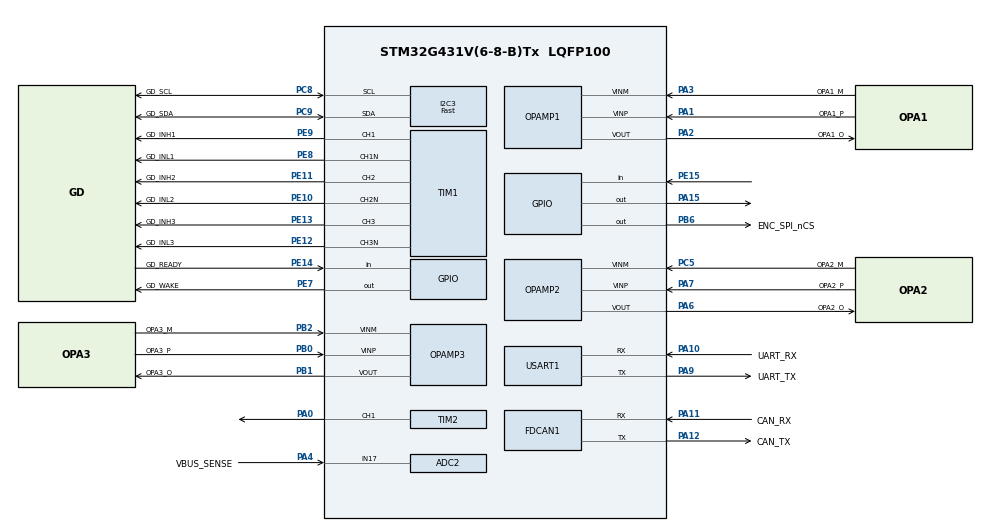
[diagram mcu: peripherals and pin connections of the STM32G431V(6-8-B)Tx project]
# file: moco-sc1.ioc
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ADC1.ClockPrescaler=ADC_CLOCK_ASYNC_DIV4
ADC1.EnableInjectedConversion=ENABLE
ADC1.EnableRegularConversion=DISABLE
ADC1.ExternalTrigInjecConv=ADC_EXTERNALTRIGINJEC_T1_TRGO
ADC1.InjNumberOfConversion=1
ADC1.InjectedChannel-1\#ChannelInjectedConversion=ADC_CHANNEL_3
ADC1.InjectedOffsetNumber-1\#ChannelInjectedConversion=ADC_OFFSET_NONE
ADC1.InjectedRank-1\#ChannelInjectedConversion=1
ADC1.InjectedSamplingTime-1\#ChannelInjectedConversion=ADC_SAMPLETIME_6CYCLES_5
ADC1.Rank1_Channel=ADC_CHANNEL_3
ADC1.master=1
ADC2.ClockPrescaler=ADC_CLOCK_ASYNC_DIV4
ADC2.EnableInjectedConversion=ENABLE
ADC2.EnableRegularConversion=DISABLE
ADC2.ExternalTrigInjecConv=ADC_EXTERNALTRIGINJEC_T1_TRGO
ADC2.InjNumberOfConversion=1
ADC2.InjectedChannel-1\#ChannelInjectedConversion=ADC_CHANNEL_3
ADC2.InjectedOffsetNumber-1\#ChannelInjectedConversion=ADC_OFFSET_NONE
ADC2.InjectedRank-1\#ChannelInjectedConversion=1
ADC2.InjectedSamplingTime-1\#ChannelInjectedConversion=ADC_SAMPLETIME_6CYCLES_5
ADC2.Overrun=ADC_OVR_DATA_OVERWRITTEN
ADC2.Rank1_Channel=ADC_CHANNEL_3
FDCAN1.CalculateBaudRateNominal=1750000
FDCAN1.CalculateTimeBitNominal=571
FDCAN1.CalculateTimeQuantumNominal=114.28571428571429
I2C3.CustomTiming=Disabled
I2C3.I2C_Speed_Mode=I2C_Fast
I2C3.Timing=0x00D04BFF
Mcu.Family=STM32G4
Mcu.Name=STM32G431V(6-8-B)Tx
Mcu.Package=LQFP100
NVIC.ADC1_2_IRQn=true\:1\:0\:true\:false\:true\:true\:true\:true
NVIC.I2C3_EV_IRQn=true\:1\:1\:true\:false\:true\:true\:true\:true
NVIC.PriorityGroup=NVIC_PRIORITYGROUP_3
NVIC.TIM2_IRQn=true\:5\:1\:true\:false\:true\:true\:true\:true
NVIC.TIM3_IRQn=true\:1\:0\:true\:false\:true\:true\:true\:true
NVIC.USART1_IRQn=true\:2\:0\:true\:false\:true\:true\:true\:true
PA0.Signal=S_TIM2_CH1
PA1.GPIO_Label=OPA1_P
PA1.Mode=Standalone
PA1.Signal=OPAMP1_VINP
PA10.GPIO_Label=UART_RX
PA10.GPIO_Speed=GPIO_SPEED_FREQ_HIGH
PA10.Mode=Asynchronous
PA10.Signal=USART1_RX
PA11.GPIO_Label=CAN_RX
PA11.GPIO_Speed=GPIO_SPEED_FREQ_HIGH
PA11.Mode=FDCAN_Activate
PA11.Signal=FDCAN1_RX
PA12.GPIO_Label=CAN_TX
PA12.GPIO_Speed=GPIO_SPEED_FREQ_HIGH
PA12.Mode=FDCAN_Activate
PA12.Signal=FDCAN1_TX
PA13.GPIO_Label=SWDIO
PA13.Mode=Serial_Wire
PA13.Signal=SYS_JTMS-SWDIO
PA14.GPIO_Label=SWCLK
PA14.Mode=Serial_Wire
PA14.Signal=SYS_JTCK-SWCLK
PA15.Signal=GPIO_Output
PA2.GPIO_Label=OPA1_O
PA2.Signal=SharedAnalog_PA2
PA3.GPIO_Label=OPA1_M
PA3.Mode=Standalone
PA3.Signal=OPAMP1_VINM
PA4.GPIO_Label=VBUS_SENSE
PA4.Mode=IN17-Single-Ended
PA4.Signal=ADC2_IN17
PA6.GPIO_Label=OPA2_O
PA6.Signal=SharedAnalog_PA6
PA7.GPIO_Label=OPA2_P
PA7.Mode=Standalone
PA7.Signal=OPAMP2_VINP
PA9.GPIO_Label=UART_TX
PA9.GPIO_Speed=GPIO_SPEED_FREQ_HIGH
PA9.Mode=Asynchronous
PA9.Signal=USART1_TX
PB0.GPIO_Label=OPA3_P
PB0.Mode=Standalone
PB0.Signal=OPAMP3_VINP
PB1.GPIO_Label=OPA3_O
PB1.Signal=SharedAnalog_PB1
PB2.GPIO_Label=OPA3_M
PB2.Mode=Standalone
PB2.Signal=OPAMP3_VINM
PB3.Signal=SPI3_SCK
PB4.GPIO_Label=ENC_SPI_MISO
PB4.GPIO_Speed=GPIO_SPEED_FREQ_HIGH
PB4.Signal=SPI1_MISO
PB5.GPIO_Label=ENC_SPI_MOSI
PB5.GPIO_Speed=GPIO_SPEED_FREQ_HIGH
PB5.Signal=SPI1_MOSI
PB6.GPIO_Label=ENC_SPI_nCS
PB6.GPIO_Speed=GPIO_SPEED_FREQ_LOW
PB6.Signal=GPIO_Output
PC5.GPIO_Label=OPA2_M
PC5.Mode=Standalone
PC5.Signal=OPAMP2_VINM
PC8.GPIO_Label=GD_SCL
PC8.GPIO_Speed=GPIO_SPEED_FREQ_HIGH
PC8.Mode=I2C
PC8.Signal=I2C3_SCL
PC9.GPIO_Label=GD_SDA
PC9.GPIO_Speed=GPIO_SPEED_FREQ_HIGH
PC9.Mode=I2C
PC9.Signal=I2C3_SDA
PE10.GPIO_Label=GD_INL2
PE10.GPIO_Speed=GPIO_SPEED_FREQ_VERY_HIGH
PE10.Mode=PWM Generation2 CH2 CH2N
PE10.Signal=TIM1_CH2N
PE11.GPIO_Label=GD_INH2
PE11.GPIO_Speed=GPIO_SPEED_FREQ_VERY_HIGH
PE11.Signal=S_TIM1_CH2
PE12.GPIO_Label=GD_INL3
PE12.GPIO_Speed=GPIO_SPEED_FREQ_VERY_HIGH
PE12.Mode=PWM Generation3 CH3 CH3N
PE12.Signal=TIM1_CH3N
PE13.GPIO_Label=GD_INH3
PE13.GPIO_Speed=GPIO_SPEED_FREQ_VERY_HIGH
PE13.Signal=S_TIM1_CH3
PE14.GPIO_Label=GD_READY
PE14.GPIO_PuPd=GPIO_PULLUP
PE14.Signal=GPIO_Input
PE15.Signal=GPIO_Input
PE7.GPIO_Label=GD_WAKE
PE7.GPIO_Speed=GPIO_SPEED_FREQ_LOW
PE7.Signal=GPIO_Output
PE8.GPIO_Label=GD_INL1
PE8.GPIO_Speed=GPIO_SPEED_FREQ_VERY_HIGH
PE8.Mode=PWM Generation1 CH1 CH1N
PE8.Signal=TIM1_CH1N
PE9.GPIO_Label=GD_INH1
PE9.GPIO_Speed=GPIO_SPEED_FREQ_VERY_HIGH
PE9.Signal=S_TIM1_CH1
PF0-OSC_IN.Mode=HSE-External-Oscillator
PF0-OSC_IN.Signal=RCC_OSC_IN
PF1-OSC_OUT.Mode=HSE-External-Oscillator
PF1-OSC_OUT.Signal=RCC_OSC_OUT
ProjectManager.HeapSize=0x200
ProjectManager.StackSize=0x400
ProjectManager.TargetToolchain=STM32CubeIDE
RCC.ADC12Freq_Value=140000000
RCC.AHBFreq_Value=140000000
RCC.APB1Freq_Value=140000000
RCC.APB1TimFreq_Value=140000000
RCC.APB2Freq_Value=140000000
RCC.APB2TimFreq_Value=140000000
RCC.CortexFreq_Value=140000000
RCC.EXTERNAL_CLOCK_VALUE=12288000
RCC.HCLKFreq_Value=140000000
RCC.HSE_VALUE=16000000
RCC.HSI48_VALUE=48000000
RCC.HSI_VALUE=16000000
RCC.LSE_VALUE=32768
RCC.PLLM=RCC_PLLM_DIV2
RCC.PLLN=35
RCC.PLLQ=RCC_PLLQ_DIV4
RCC.SYSCLKFreq_VALUE=140000000
RCC.SYSCLKSource=RCC_SYSCLKSOURCE_PLLCLK
RCC.USBFreq_Value=70000000
RCC.VCOOutputFreq_Value=280000000
SH.S_TIM1_CH1.0=TIM1_CH1,PWM Generation1 CH1 CH1N
SH.S_TIM1_CH2.0=TIM1_CH2,PWM Generation2 CH2 CH2N
SH.S_TIM1_CH3.0=TIM1_CH3,PWM Generation3 CH3 CH3N
SH.S_TIM2_CH1.0=TIM2_CH1,PWM Generation1 CH1
SH.SharedAnalog_PA2.0=OPAMP1_VOUT,Standalone
SH.SharedAnalog_PA2.1=ADC1_IN3,IN3-Single-Ended
SH.SharedAnalog_PA6.0=OPAMP2_VOUT,Standalone
SH.SharedAnalog_PA6.1=ADC2_IN3,IN3-Single-Ended
SH.SharedAnalog_PB1.0=OPAMP3_VOUT,Standalone
SH.SharedAnalog_PB1.1=ADC1_IN12,IN12-Single-Ended
STMicroelectronics.X-CUBE-AZRTOS-G4.2.0.0.TX_APP_CREATION=1
STMicroelectronics.X-CUBE-AZRTOS-G4.2.0.0.TX_APP_GENERATE_INIT_CODE=true
STMicroelectronics.X-CUBE-AZRTOS-G4.2.0.0_IsAnAzureRtosMw=true
TIM1.AutoReloadPreload=TIM_AUTORELOAD_PRELOAD_DISABLE
TIM1.Break2Polarity=TIM_BREAK2POLARITY_LOW
TIM1.BreakPolarity=TIM_BREAKPOLARITY_LOW
TIM1.Channel-PWM\ Generation1\ CH1\ CH1N=TIM_CHANNEL_1
TIM1.Channel-PWM\ Generation2\ CH2\ CH2N=TIM_CHANNEL_2
TIM1.Channel-PWM\ Generation3\ CH3\ CH3N=TIM_CHANNEL_3
TIM1.Channel-PWM\ Generation4\ No\ Output=TIM_CHANNEL_4
TIM1.ClockDivision=TIM_CLOCKDIVISION_DIV1
TIM1.CounterMode=TIM_COUNTERMODE_CENTERALIGNED1
TIM1.DeadTime=GD_PWM_TIM_DTG
TIM1.OCMode_PWM-PWM\ Generation4\ No\ Output=TIM_OCMODE_PWM2
TIM1.OCNPolarity_1=TIM_OCNPOLARITY_HIGH
TIM1.OCNPolarity_2=TIM_OCNPOLARITY_HIGH
TIM1.OCNPolarity_3=TIM_OCNPOLARITY_HIGH
TIM1.PeriodNoDither=GD_PWM_TIM_ARR
TIM1.Prescaler=GD_PWM_TIM_PSC
TIM1.PulseNoDither_1=0
TIM1.PulseNoDither_2=0
TIM1.PulseNoDither_3=0
TIM1.RepetitionCounter=0
TIM1.TIM_MasterOutputTrigger=TIM_TRGO_OC4REF
TIM2.AutoReloadPreload=TIM_AUTORELOAD_PRELOAD_DISABLE
TIM2.Channel-PWM\ Generation1\ CH1=TIM_CHANNEL_1
TIM2.PeriodNoDither=HB_LED_TIM_ARR
TIM2.Prescaler=HB_LED_TIM_PSC
TIM3.PeriodNoDither=ML_TIM_ARR
TIM3.Prescaler=ML_TIM_PSC
TIM8.PeriodNoDither=249
TIM8.Prescaler=27
USART1.FIFOMode=FIFOMODE_ENABLE
USART1.VirtualMode-Asynchronous=VM_ASYNC
VP_SYS_VS_DBSignals.Mode=DisableDeadBatterySignals
VP_SYS_V_VREFBUF.Mode=ExternalMode
VP_TIM16_VS_ClockSourceINT.Mode=Enable_Timer
VP_TIM1_VS_ClockSourceINT.Mode=Internal
VP_TIM1_VS_no_output4.Mode=PWM Generation4 No Output
VP_TIM2_VS_ClockSourceINT.Mode=Internal
VP_TIM3_VS_ClockSourceINT.Mode=Internal
VP_TIM8_VS_ClockSourceINT.Mode=Internal
board=custom

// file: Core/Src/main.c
/* USER CODE BEGIN Header */
/**
  ******************************************************************************
  * @file           : main.c
  * @brief          : Main program body
  ******************************************************************************
  * @attention
  *
  * Copyright (c) 2024 STMicroelectronics.
  * All rights reserved.
  *
  * This software is licensed under terms that can be found in the LICENSE file
  * in the root directory of this software component.
  * If no LICENSE file comes with this software, it is provided AS-IS.
  *
  ******************************************************************************
  */
/* USER CODE END Header */
#include "main.h"

/* USER CODE BEGIN Includes */
#include "stspin32g4_gate_driver.h"
#include "heartbeat.h"
#include "stspin32g4.h"
/* USER CODE END Includes */

FDCAN_HandleTypeDef hfdcan1;

OPAMP_HandleTypeDef hopamp1;
OPAMP_HandleTypeDef hopamp2;
OPAMP_HandleTypeDef hopamp3;

void SystemClock_Config(void);
static void MX_GPIO_Init(void);
static void MX_ADC2_Init(void);
static void MX_FDCAN1_Init(void);
static void MX_I2C3_Init(void);
static void MX_OPAMP1_Init(void);
static void MX_OPAMP2_Init(void);
static void MX_OPAMP3_Init(void);
static void MX_TIM1_Init(void);
static void MX_TIM16_Init(void);
static void MX_USART1_UART_Init(void);
static void MX_TIM2_Init(void);
static void MX_TIM8_Init(void);
static void MX_TIM3_Init(void);
static void MX_ADC1_Init(void);

/* USER CODE BEGIN 0 */
extern float act;
/* USER CODE END 0 */

int main(void)
{

  /* MCU Configuration--------------------------------------------------------*/

  /* Reset of all peripherals, Initializes the Flash interface and the Systick. */
  HAL_Init();

  /* Configure the system clock */
  SystemClock_Config();

  /* Initialize all configured peripherals */
  MX_GPIO_Init();
  MX_ADC2_Init();
  MX_FDCAN1_Init();
  MX_I2C3_Init();
  MX_OPAMP1_Init();
  MX_OPAMP2_Init();
  MX_OPAMP3_Init();
  MX_TIM1_Init();
  MX_TIM16_Init();
  MX_USART1_UART_Init();
  MX_TIM2_Init();
  MX_TIM8_Init();
  MX_TIM3_Init();
  MX_ADC1_Init();
  /* USER CODE BEGIN 2 */
  heartbeat_init();
  spg4_init();
  gd_init();
  /* USER CODE END 2 */

  /* Infinite loop */
  /* USER CODE BEGIN WHILE */
  LL_USART_TransmitData8(USART1, 0x41);
  while (1)
  {
    /* USER CODE END WHILE */

    /* USER CODE BEGIN 3 */
    LL_USART_TransmitData8(USART1, act);
    LL_USART_TransmitData8(USART1, 0xFE);
    gd_clear_fault();

    //LL_USART_TransmitData8(USART1, (uint8_t)vbus_adc);

    //spg4_set_pwm(60, 0, 0);
    HAL_Delay(500);
  }
  /* USER CODE END 3 */
}

void SystemClock_Config(void)
{
  LL_FLASH_SetLatency(LL_FLASH_LATENCY_4);
  while(LL_FLASH_GetLatency() != LL_FLASH_LATENCY_4)
  {
  }
  LL_PWR_SetRegulVoltageScaling(LL_PWR_REGU_VOLTAGE_SCALE1);
  LL_RCC_HSI_Enable();
   /* Wait till HSI is ready */
  while(LL_RCC_HSI_IsReady() != 1)
  {
  }

  LL_RCC_HSI_SetCalibTrimming(64);
  LL_RCC_PLL_ConfigDomain_SYS(LL_RCC_PLLSOURCE_HSI, LL_RCC_PLLM_DIV_2, 35, LL_RCC_PLLR_DIV_2);
  LL_RCC_PLL_EnableDomain_SYS();
  LL_RCC_PLL_Enable();
   /* Wait till PLL is ready */
  while(LL_RCC_PLL_IsReady() != 1)
  {
  }

  LL_RCC_SetSysClkSource(LL_RCC_SYS_CLKSOURCE_PLL);
  LL_RCC_SetAHBPrescaler(LL_RCC_SYSCLK_DIV_2);
   /* Wait till System clock is ready */
  while(LL_RCC_GetSysClkSource() != LL_RCC_SYS_CLKSOURCE_STATUS_PLL)
  {
  }

  /* Insure 1us transition state at intermediate medium speed clock*/
  for (__IO uint32_t i = (170 >> 1); i !=0; i--);

  /* Set AHB prescaler*/
  LL_RCC_SetAHBPrescaler(LL_RCC_SYSCLK_DIV_1);
  LL_RCC_SetAPB1Prescaler(LL_RCC_APB1_DIV_1);
  LL_RCC_SetAPB2Prescaler(LL_RCC_APB2_DIV_1);
  LL_SetSystemCoreClock(140000000);

   /* Update the time base */
  if (HAL_InitTick (TICK_INT_PRIORITY) != HAL_OK)
  {
    Error_Handler();
  }
}

static void MX_ADC1_Init(void)
{

  LL_ADC_InitTypeDef ADC_InitStruct = {0};
  LL_ADC_REG_InitTypeDef ADC_REG_InitStruct = {0};
  LL_ADC_CommonInitTypeDef ADC_CommonInitStruct = {0};
  LL_ADC_INJ_InitTypeDef ADC_INJ_InitStruct = {0};

  LL_GPIO_InitTypeDef GPIO_InitStruct = {0};

  LL_RCC_SetADCClockSource(LL_RCC_ADC12_CLKSOURCE_SYSCLK);

  /* Peripheral clock enable */
  LL_AHB2_GRP1_EnableClock(LL_AHB2_GRP1_PERIPH_ADC12);

  LL_AHB2_GRP1_EnableClock(LL_AHB2_GRP1_PERIPH_GPIOA);
  LL_AHB2_GRP1_EnableClock(LL_AHB2_GRP1_PERIPH_GPIOB);
  /**ADC1 GPIO Configuration
  PA2   ------> ADC1_IN3
  PB1   ------> ADC1_IN12
  */
  GPIO_InitStruct.Pin = OPA1_O_Pin;
  GPIO_InitStruct.Mode = LL_GPIO_MODE_ANALOG;
  GPIO_InitStruct.Pull = LL_GPIO_PULL_NO;
  LL_GPIO_Init(OPA1_O_GPIO_Port, &GPIO_InitStruct);

  GPIO_InitStruct.Pin = OPA3_O_Pin;
  GPIO_InitStruct.Mode = LL_GPIO_MODE_ANALOG;
  GPIO_InitStruct.Pull = LL_GPIO_PULL_NO;
  LL_GPIO_Init(OPA3_O_GPIO_Port, &GPIO_InitStruct);

  /* ADC1 interrupt Init */
  NVIC_SetPriority(ADC1_2_IRQn, NVIC_EncodePriority(NVIC_GetPriorityGrouping(),1, 0));
  NVIC_EnableIRQ(ADC1_2_IRQn);

  /** Common config
  */
  ADC_InitStruct.Resolution = LL_ADC_RESOLUTION_12B;
  ADC_InitStruct.DataAlignment = LL_ADC_DATA_ALIGN_RIGHT;
  ADC_InitStruct.LowPowerMode = LL_ADC_LP_MODE_NONE;
  LL_ADC_Init(ADC1, &ADC_InitStruct);
  ADC_REG_InitStruct.SequencerLength = LL_ADC_REG_SEQ_SCAN_DISABLE;
  ADC_REG_InitStruct.SequencerDiscont = LL_ADC_REG_SEQ_DISCONT_DISABLE;
  ADC_REG_InitStruct.ContinuousMode = LL_ADC_REG_CONV_SINGLE;
  ADC_REG_InitStruct.DMATransfer = LL_ADC_REG_DMA_TRANSFER_NONE;
  ADC_REG_InitStruct.Overrun = LL_ADC_REG_OVR_DATA_PRESERVED;
  LL_ADC_REG_Init(ADC1, &ADC_REG_InitStruct);
  LL_ADC_SetGainCompensation(ADC1, 0);
  LL_ADC_SetOverSamplingScope(ADC1, LL_ADC_OVS_DISABLE);
  ADC_CommonInitStruct.CommonClock = LL_ADC_CLOCK_ASYNC_DIV4;
  ADC_CommonInitStruct.Multimode = LL_ADC_MULTI_INDEPENDENT;
  LL_ADC_CommonInit(__LL_ADC_COMMON_INSTANCE(ADC1), &ADC_CommonInitStruct);
  ADC_INJ_InitStruct.TriggerSource = LL_ADC_INJ_TRIG_EXT_TIM1_TRGO;
  ADC_INJ_InitStruct.SequencerLength = LL_ADC_INJ_SEQ_SCAN_DISABLE;
  ADC_INJ_InitStruct.SequencerDiscont = LL_ADC_INJ_SEQ_DISCONT_DISABLE;
  ADC_INJ_InitStruct.TrigAuto = LL_ADC_INJ_TRIG_INDEPENDENT;
  LL_ADC_INJ_Init(ADC1, &ADC_INJ_InitStruct);
  LL_ADC_INJ_SetQueueMode(ADC1, LL_ADC_INJ_QUEUE_DISABLE);
  LL_ADC_INJ_SetTriggerEdge(ADC1, LL_ADC_INJ_TRIG_EXT_RISING);

  /* Disable ADC deep power down (enabled by default after reset state) */
  LL_ADC_DisableDeepPowerDown(ADC1);
  /* Enable ADC internal voltage regulator */
  LL_ADC_EnableInternalRegulator(ADC1);
  /* Delay for ADC internal voltage regulator stabilization. */
  /* Compute number of CPU cycles to wait for, from delay in us. */
  /* Note: Variable divided by 2 to compensate partially */
  /* CPU processing cycles (depends on compilation optimization). */
  /* Note: If system core clock frequency is below 200kHz, wait time */
  /* is only a few CPU processing cycles. */
  uint32_t wait_loop_index;
  wait_loop_index = ((LL_ADC_DELAY_INTERNAL_REGUL_STAB_US * (SystemCoreClock / (100000 * 2))) / 10);
  while(wait_loop_index != 0)
  {
    wait_loop_index--;
  }

  /** Configure Injected Channel
  */
  LL_ADC_INJ_SetSequencerRanks(ADC1, LL_ADC_INJ_RANK_1, LL_ADC_CHANNEL_3);
  LL_ADC_SetChannelSamplingTime(ADC1, LL_ADC_CHANNEL_3, LL_ADC_SAMPLINGTIME_6CYCLES_5);
  LL_ADC_SetChannelSingleDiff(ADC1, LL_ADC_CHANNEL_3, LL_ADC_SINGLE_ENDED);

}

static void MX_ADC2_Init(void)
{

  LL_ADC_InitTypeDef ADC_InitStruct = {0};
  LL_ADC_REG_InitTypeDef ADC_REG_InitStruct = {0};
  LL_ADC_INJ_InitTypeDef ADC_INJ_InitStruct = {0};

  LL_GPIO_InitTypeDef GPIO_InitStruct = {0};

  LL_RCC_SetADCClockSource(LL_RCC_ADC12_CLKSOURCE_SYSCLK);

  /* Peripheral clock enable */
  LL_AHB2_GRP1_EnableClock(LL_AHB2_GRP1_PERIPH_ADC12);

  LL_AHB2_GRP1_EnableClock(LL_AHB2_GRP1_PERIPH_GPIOA);
  /**ADC2 GPIO Configuration
  PA4   ------> ADC2_IN17
  PA6   ------> ADC2_IN3
  */
  GPIO_InitStruct.Pin = VBUS_SENSE_Pin;
  GPIO_InitStruct.Mode = LL_GPIO_MODE_ANALOG;
  GPIO_InitStruct.Pull = LL_GPIO_PULL_NO;
  LL_GPIO_Init(VBUS_SENSE_GPIO_Port, &GPIO_InitStruct);

  GPIO_InitStruct.Pin = OPA2_O_Pin;
  GPIO_InitStruct.Mode = LL_GPIO_MODE_ANALOG;
  GPIO_InitStruct.Pull = LL_GPIO_PULL_NO;
  LL_GPIO_Init(OPA2_O_GPIO_Port, &GPIO_InitStruct);

  /* ADC2 interrupt Init */
  NVIC_SetPriority(ADC1_2_IRQn, NVIC_EncodePriority(NVIC_GetPriorityGrouping(),1, 0));
  NVIC_EnableIRQ(ADC1_2_IRQn);

  /** Common config
  */
  ADC_InitStruct.Resolution = LL_ADC_RESOLUTION_12B;
  ADC_InitStruct.DataAlignment = LL_ADC_DATA_ALIGN_RIGHT;
  ADC_InitStruct.LowPowerMode = LL_ADC_LP_MODE_NONE;
  LL_ADC_Init(ADC2, &ADC_InitStruct);
  ADC_REG_InitStruct.SequencerLength = LL_ADC_REG_SEQ_SCAN_DISABLE;
  ADC_REG_InitStruct.SequencerDiscont = LL_ADC_REG_SEQ_DISCONT_DISABLE;
  ADC_REG_InitStruct.ContinuousMode = LL_ADC_REG_CONV_SINGLE;
  ADC_REG_InitStruct.DMATransfer = LL_ADC_REG_DMA_TRANSFER_NONE;
  ADC_REG_InitStruct.Overrun = LL_ADC_REG_OVR_DATA_OVERWRITTEN;
  LL_ADC_REG_Init(ADC2, &ADC_REG_InitStruct);
  LL_ADC_SetGainCompensation(ADC2, 0);
  LL_ADC_SetOverSamplingScope(ADC2, LL_ADC_OVS_DISABLE);
  ADC_INJ_InitStruct.TriggerSource = LL_ADC_INJ_TRIG_EXT_TIM1_TRGO;
  ADC_INJ_InitStruct.SequencerLength = LL_ADC_INJ_SEQ_SCAN_DISABLE;
  ADC_INJ_InitStruct.SequencerDiscont = LL_ADC_INJ_SEQ_DISCONT_DISABLE;
  ADC_INJ_InitStruct.TrigAuto = LL_ADC_INJ_TRIG_INDEPENDENT;
  LL_ADC_INJ_Init(ADC2, &ADC_INJ_InitStruct);
  LL_ADC_INJ_SetQueueMode(ADC2, LL_ADC_INJ_QUEUE_DISABLE);
  LL_ADC_INJ_SetTriggerEdge(ADC2, LL_ADC_INJ_TRIG_EXT_RISING);

  /* Disable ADC deep power down (enabled by default after reset state) */
  LL_ADC_DisableDeepPowerDown(ADC2);
  /* Enable ADC internal voltage regulator */
  LL_ADC_EnableInternalRegulator(ADC2);
  /* Delay for ADC internal voltage regulator stabilization. */
  /* Compute number of CPU cycles to wait for, from delay in us. */
  /* Note: Variable divided by 2 to compensate partially */
  /* CPU processing cycles (depends on compilation optimization). */
  /* Note: If system core clock frequency is below 200kHz, wait time */
  /* is only a few CPU processing cycles. */
  uint32_t wait_loop_index;
  wait_loop_index = ((LL_ADC_DELAY_INTERNAL_REGUL_STAB_US * (SystemCoreClock / (100000 * 2))) / 10);
  while(wait_loop_index != 0)
  {
    wait_loop_index--;
  }

  /** Configure Injected Channel
  */
  LL_ADC_INJ_SetSequencerRanks(ADC2, LL_ADC_INJ_RANK_1, LL_ADC_CHANNEL_3);
  LL_ADC_SetChannelSamplingTime(ADC2, LL_ADC_CHANNEL_3, LL_ADC_SAMPLINGTIME_6CYCLES_5);
  LL_ADC_SetChannelSingleDiff(ADC2, LL_ADC_CHANNEL_3, LL_ADC_SINGLE_ENDED);

}

static void MX_FDCAN1_Init(void)
{

  hfdcan1.Instance = FDCAN1;
  hfdcan1.Init.ClockDivider = FDCAN_CLOCK_DIV1;
  hfdcan1.Init.FrameFormat = FDCAN_FRAME_CLASSIC;
  hfdcan1.Init.Mode = FDCAN_MODE_NORMAL;
  hfdcan1.Init.AutoRetransmission = DISABLE;
  hfdcan1.Init.TransmitPause = DISABLE;
  hfdcan1.Init.ProtocolException = DISABLE;
  hfdcan1.Init.NominalPrescaler = 16;
  hfdcan1.Init.NominalSyncJumpWidth = 1;
  hfdcan1.Init.NominalTimeSeg1 = 2;
  hfdcan1.Init.NominalTimeSeg2 = 2;
  hfdcan1.Init.DataPrescaler = 1;
  hfdcan1.Init.DataSyncJumpWidth = 1;
  hfdcan1.Init.DataTimeSeg1 = 1;
  hfdcan1.Init.DataTimeSeg2 = 1;
  hfdcan1.Init.StdFiltersNbr = 0;
  hfdcan1.Init.ExtFiltersNbr = 0;
  hfdcan1.Init.TxFifoQueueMode = FDCAN_TX_FIFO_OPERATION;
  if (HAL_FDCAN_Init(&hfdcan1) != HAL_OK)
  {
    Error_Handler();
  }

}

static void MX_I2C3_Init(void)
{

  LL_I2C_InitTypeDef I2C_InitStruct = {0};

  LL_GPIO_InitTypeDef GPIO_InitStruct = {0};

  LL_RCC_SetI2CClockSource(LL_RCC_I2C3_CLKSOURCE_PCLK1);

  LL_AHB2_GRP1_EnableClock(LL_AHB2_GRP1_PERIPH_GPIOC);
  /**I2C3 GPIO Configuration
  PC8   ------> I2C3_SCL
  PC9   ------> I2C3_SDA
  */
  GPIO_InitStruct.Pin = GD_SCL_Pin;
  GPIO_InitStruct.Mode = LL_GPIO_MODE_ALTERNATE;
  GPIO_InitStruct.Speed = LL_GPIO_SPEED_FREQ_HIGH;
  GPIO_InitStruct.OutputType = LL_GPIO_OUTPUT_OPENDRAIN;
  GPIO_InitStruct.Pull = LL_GPIO_PULL_NO;
  GPIO_InitStruct.Alternate = LL_GPIO_AF_8;
  LL_GPIO_Init(GD_SCL_GPIO_Port, &GPIO_InitStruct);

  GPIO_InitStruct.Pin = GD_SDA_Pin;
  GPIO_InitStruct.Mode = LL_GPIO_MODE_ALTERNATE;
  GPIO_InitStruct.Speed = LL_GPIO_SPEED_FREQ_HIGH;
  GPIO_InitStruct.OutputType = LL_GPIO_OUTPUT_OPENDRAIN;
  GPIO_InitStruct.Pull = LL_GPIO_PULL_NO;
  GPIO_InitStruct.Alternate = LL_GPIO_AF_8;
  LL_GPIO_Init(GD_SDA_GPIO_Port, &GPIO_InitStruct);

  /* Peripheral clock enable */
  LL_APB1_GRP1_EnableClock(LL_APB1_GRP1_PERIPH_I2C3);

  /* I2C3 interrupt Init */
  NVIC_SetPriority(I2C3_EV_IRQn, NVIC_EncodePriority(NVIC_GetPriorityGrouping(),1, 1));
  NVIC_EnableIRQ(I2C3_EV_IRQn);

  /** I2C Initialization
  */
  I2C_InitStruct.PeripheralMode = LL_I2C_MODE_I2C;
  I2C_InitStruct.Timing = 0x00D04BFF;
  I2C_InitStruct.AnalogFilter = LL_I2C_ANALOGFILTER_ENABLE;
  I2C_InitStruct.DigitalFilter = 0;
  I2C_InitStruct.OwnAddress1 = 0;
  I2C_InitStruct.TypeAcknowledge = LL_I2C_ACK;
  I2C_InitStruct.OwnAddrSize = LL_I2C_OWNADDRESS1_7BIT;
  LL_I2C_Init(I2C3, &I2C_InitStruct);
  LL_I2C_EnableAutoEndMode(I2C3);
  LL_I2C_SetOwnAddress2(I2C3, 0, LL_I2C_OWNADDRESS2_NOMASK);
  LL_I2C_DisableOwnAddress2(I2C3);
  LL_I2C_DisableGeneralCall(I2C3);
  LL_I2C_EnableClockStretching(I2C3);

}

static void MX_OPAMP1_Init(void)
{

  hopamp1.Instance = OPAMP1;
  hopamp1.Init.PowerMode = OPAMP_POWERMODE_NORMAL;
  hopamp1.Init.Mode = OPAMP_STANDALONE_MODE;
  hopamp1.Init.InvertingInput = OPAMP_INVERTINGINPUT_IO0;
  hopamp1.Init.NonInvertingInput = OPAMP_NONINVERTINGINPUT_IO0;
  hopamp1.Init.InternalOutput = DISABLE;
  hopamp1.Init.TimerControlledMuxmode = OPAMP_TIMERCONTROLLEDMUXMODE_DISABLE;
  hopamp1.Init.UserTrimming = OPAMP_TRIMMING_FACTORY;
  if (HAL_OPAMP_Init(&hopamp1) != HAL_OK)
  {
    Error_Handler();
  }

}

static void MX_OPAMP2_Init(void)
{

  hopamp2.Instance = OPAMP2;
  hopamp2.Init.PowerMode = OPAMP_POWERMODE_NORMAL;
  hopamp2.Init.Mode = OPAMP_STANDALONE_MODE;
  hopamp2.Init.InvertingInput = OPAMP_INVERTINGINPUT_IO1;
  hopamp2.Init.NonInvertingInput = OPAMP_NONINVERTINGINPUT_IO0;
  hopamp2.Init.InternalOutput = DISABLE;
  hopamp2.Init.TimerControlledMuxmode = OPAMP_TIMERCONTROLLEDMUXMODE_DISABLE;
  hopamp2.Init.UserTrimming = OPAMP_TRIMMING_FACTORY;
  if (HAL_OPAMP_Init(&hopamp2) != HAL_OK)
  {
    Error_Handler();
  }

}

static void MX_OPAMP3_Init(void)
{

  hopamp3.Instance = OPAMP3;
  hopamp3.Init.PowerMode = OPAMP_POWERMODE_NORMAL;
  hopamp3.Init.Mode = OPAMP_STANDALONE_MODE;
  hopamp3.Init.InvertingInput = OPAMP_INVERTINGINPUT_IO0;
  hopamp3.Init.NonInvertingInput = OPAMP_NONINVERTINGINPUT_IO0;
  hopamp3.Init.InternalOutput = DISABLE;
  hopamp3.Init.TimerControlledMuxmode = OPAMP_TIMERCONTROLLEDMUXMODE_DISABLE;
  hopamp3.Init.UserTrimming = OPAMP_TRIMMING_FACTORY;
  if (HAL_OPAMP_Init(&hopamp3) != HAL_OK)
  {
    Error_Handler();
  }

}

static void MX_TIM1_Init(void)
{

  LL_TIM_InitTypeDef TIM_InitStruct = {0};
  LL_TIM_OC_InitTypeDef TIM_OC_InitStruct = {0};
  LL_TIM_BDTR_InitTypeDef TIM_BDTRInitStruct = {0};

  LL_GPIO_InitTypeDef GPIO_InitStruct = {0};

  /* Peripheral clock enable */
  LL_APB2_GRP1_EnableClock(LL_APB2_GRP1_PERIPH_TIM1);

  TIM_InitStruct.Prescaler = GD_PWM_TIM_PSC;
  TIM_InitStruct.CounterMode = LL_TIM_COUNTERMODE_CENTER_DOWN;
  TIM_InitStruct.Autoreload = GD_PWM_TIM_ARR;
  TIM_InitStruct.ClockDivision = LL_TIM_CLOCKDIVISION_DIV1;
  TIM_InitStruct.RepetitionCounter = 0;
  LL_TIM_Init(TIM1, &TIM_InitStruct);
  LL_TIM_DisableARRPreload(TIM1);
  LL_TIM_SetClockSource(TIM1, LL_TIM_CLOCKSOURCE_INTERNAL);
  LL_TIM_OC_EnablePreload(TIM1, LL_TIM_CHANNEL_CH1);
  TIM_OC_InitStruct.OCMode = LL_TIM_OCMODE_PWM1;
  TIM_OC_InitStruct.OCState = LL_TIM_OCSTATE_DISABLE;
  TIM_OC_InitStruct.OCNState = LL_TIM_OCSTATE_DISABLE;
  TIM_OC_InitStruct.CompareValue = 0;
  TIM_OC_InitStruct.OCPolarity = LL_TIM_OCPOLARITY_HIGH;
  TIM_OC_InitStruct.OCNPolarity = LL_TIM_OCPOLARITY_HIGH;
  TIM_OC_InitStruct.OCIdleState = LL_TIM_OCIDLESTATE_LOW;
  TIM_OC_InitStruct.OCNIdleState = LL_TIM_OCIDLESTATE_LOW;
  LL_TIM_OC_Init(TIM1, LL_TIM_CHANNEL_CH1, &TIM_OC_InitStruct);
  LL_TIM_OC_DisableFast(TIM1, LL_TIM_CHANNEL_CH1);
  LL_TIM_OC_EnablePreload(TIM1, LL_TIM_CHANNEL_CH2);
  LL_TIM_OC_Init(TIM1, LL_TIM_CHANNEL_CH2, &TIM_OC_InitStruct);
  LL_TIM_OC_DisableFast(TIM1, LL_TIM_CHANNEL_CH2);
  LL_TIM_OC_EnablePreload(TIM1, LL_TIM_CHANNEL_CH3);
  LL_TIM_OC_Init(TIM1, LL_TIM_CHANNEL_CH3, &TIM_OC_InitStruct);
  LL_TIM_OC_DisableFast(TIM1, LL_TIM_CHANNEL_CH3);
  LL_TIM_OC_EnablePreload(TIM1, LL_TIM_CHANNEL_CH4);
  TIM_OC_InitStruct.OCMode = LL_TIM_OCMODE_PWM2;
  LL_TIM_OC_Init(TIM1, LL_TIM_CHANNEL_CH4, &TIM_OC_InitStruct);
  LL_TIM_OC_DisableFast(TIM1, LL_TIM_CHANNEL_CH4);
  LL_TIM_SetTriggerOutput(TIM1, LL_TIM_TRGO_OC4REF);
  LL_TIM_SetTriggerOutput2(TIM1, LL_TIM_TRGO2_RESET);
  LL_TIM_DisableMasterSlaveMode(TIM1);
  TIM_BDTRInitStruct.OSSRState = LL_TIM_OSSR_DISABLE;
  TIM_BDTRInitStruct.OSSIState = LL_TIM_OSSI_DISABLE;
  TIM_BDTRInitStruct.LockLevel = LL_TIM_LOCKLEVEL_OFF;
  TIM_BDTRInitStruct.DeadTime = GD_PWM_TIM_DTG;
  TIM_BDTRInitStruct.BreakState = LL_TIM_BREAK_DISABLE;
  TIM_BDTRInitStruct.BreakPolarity = LL_TIM_BREAK_POLARITY_LOW;
  TIM_BDTRInitStruct.BreakFilter = LL_TIM_BREAK_FILTER_FDIV1;
  TIM_BDTRInitStruct.BreakAFMode = LL_TIM_BREAK_AFMODE_INPUT;
  TIM_BDTRInitStruct.Break2State = LL_TIM_BREAK2_DISABLE;
  TIM_BDTRInitStruct.Break2Polarity = LL_TIM_BREAK2_POLARITY_LOW;
  TIM_BDTRInitStruct.Break2Filter = LL_TIM_BREAK2_FILTER_FDIV1;
  TIM_BDTRInitStruct.Break2AFMode = LL_TIM_BREAK_AFMODE_INPUT;
  TIM_BDTRInitStruct.AutomaticOutput = LL_TIM_AUTOMATICOUTPUT_DISABLE;
  LL_TIM_BDTR_Init(TIM1, &TIM_BDTRInitStruct);
  LL_AHB2_GRP1_EnableClock(LL_AHB2_GRP1_PERIPH_GPIOE);
  /**TIM1 GPIO Configuration
  PE8   ------> TIM1_CH1N
  PE9   ------> TIM1_CH1
  PE10   ------> TIM1_CH2N
  PE11   ------> TIM1_CH2
  PE12   ------> TIM1_CH3N
  PE13   ------> TIM1_CH3
  */
  GPIO_InitStruct.Pin = GD_INL1_Pin;
  GPIO_InitStruct.Mode = LL_GPIO_MODE_ALTERNATE;
  GPIO_InitStruct.Speed = LL_GPIO_SPEED_FREQ_VERY_HIGH;
  GPIO_InitStruct.OutputType = LL_GPIO_OUTPUT_PUSHPULL;
  GPIO_InitStruct.Pull = LL_GPIO_PULL_NO;
  GPIO_InitStruct.Alternate = LL_GPIO_AF_2;
  LL_GPIO_Init(GD_INL1_GPIO_Port, &GPIO_InitStruct);

  GPIO_InitStruct.Pin = GD_INH1_Pin;
  GPIO_InitStruct.Mode = LL_GPIO_MODE_ALTERNATE;
  GPIO_InitStruct.Speed = LL_GPIO_SPEED_FREQ_VERY_HIGH;
  GPIO_InitStruct.OutputType = LL_GPIO_OUTPUT_PUSHPULL;
  GPIO_InitStruct.Pull = LL_GPIO_PULL_NO;
  GPIO_InitStruct.Alternate = LL_GPIO_AF_2;
  LL_GPIO_Init(GD_INH1_GPIO_Port, &GPIO_InitStruct);

  GPIO_InitStruct.Pin = GD_INL2_Pin;
  GPIO_InitStruct.Mode = LL_GPIO_MODE_ALTERNATE;
  GPIO_InitStruct.Speed = LL_GPIO_SPEED_FREQ_VERY_HIGH;
  GPIO_InitStruct.OutputType = LL_GPIO_OUTPUT_PUSHPULL;
  GPIO_InitStruct.Pull = LL_GPIO_PULL_NO;
  GPIO_InitStruct.Alternate = LL_GPIO_AF_2;
  LL_GPIO_Init(GD_INL2_GPIO_Port, &GPIO_InitStruct);

  GPIO_InitStruct.Pin = GD_INH2_Pin;
  GPIO_InitStruct.Mode = LL_GPIO_MODE_ALTERNATE;
  GPIO_InitStruct.Speed = LL_GPIO_SPEED_FREQ_VERY_HIGH;
  GPIO_InitStruct.OutputType = LL_GPIO_OUTPUT_PUSHPULL;
  GPIO_InitStruct.Pull = LL_GPIO_PULL_NO;
  GPIO_InitStruct.Alternate = LL_GPIO_AF_2;
  LL_GPIO_Init(GD_INH2_GPIO_Port, &GPIO_InitStruct);

  GPIO_InitStruct.Pin = GD_INL3_Pin;
  GPIO_InitStruct.Mode = LL_GPIO_MODE_ALTERNATE;
  GPIO_InitStruct.Speed = LL_GPIO_SPEED_FREQ_VERY_HIGH;
  GPIO_InitStruct.OutputType = LL_GPIO_OUTPUT_PUSHPULL;
  GPIO_InitStruct.Pull = LL_GPIO_PULL_NO;
  GPIO_InitStruct.Alternate = LL_GPIO_AF_2;
  LL_GPIO_Init(GD_INL3_GPIO_Port, &GPIO_InitStruct);

  GPIO_InitStruct.Pin = GD_INH3_Pin;
  GPIO_InitStruct.Mode = LL_GPIO_MODE_ALTERNATE;
  GPIO_InitStruct.Speed = LL_GPIO_SPEED_FREQ_VERY_HIGH;
  GPIO_InitStruct.OutputType = LL_GPIO_OUTPUT_PUSHPULL;
  GPIO_InitStruct.Pull = LL_GPIO_PULL_NO;
  GPIO_InitStruct.Alternate = LL_GPIO_AF_2;
  LL_GPIO_Init(GD_INH3_GPIO_Port, &GPIO_InitStruct);

}

static void MX_TIM2_Init(void)
{

  LL_TIM_InitTypeDef TIM_InitStruct = {0};
  LL_TIM_OC_InitTypeDef TIM_OC_InitStruct = {0};

  LL_GPIO_InitTypeDef GPIO_InitStruct = {0};

  /* Peripheral clock enable */
  LL_APB1_GRP1_EnableClock(LL_APB1_GRP1_PERIPH_TIM2);

  /* TIM2 interrupt Init */
  NVIC_SetPriority(TIM2_IRQn, NVIC_EncodePriority(NVIC_GetPriorityGrouping(),5, 1));
  NVIC_EnableIRQ(TIM2_IRQn);

  TIM_InitStruct.Prescaler = HB_LED_TIM_PSC;
  TIM_InitStruct.CounterMode = LL_TIM_COUNTERMODE_UP;
  TIM_InitStruct.Autoreload = HB_LED_TIM_ARR;
  TIM_InitStruct.ClockDivision = LL_TIM_CLOCKDIVISION_DIV1;
  LL_TIM_Init(TIM2, &TIM_InitStruct);
  LL_TIM_DisableARRPreload(TIM2);
  LL_TIM_SetClockSource(TIM2, LL_TIM_CLOCKSOURCE_INTERNAL);
  LL_TIM_OC_EnablePreload(TIM2, LL_TIM_CHANNEL_CH1);
  TIM_OC_InitStruct.OCMode = LL_TIM_OCMODE_PWM1;
  TIM_OC_InitStruct.OCState = LL_TIM_OCSTATE_DISABLE;
  TIM_OC_InitStruct.OCNState = LL_TIM_OCSTATE_DISABLE;
  TIM_OC_InitStruct.CompareValue = 0;
  TIM_OC_InitStruct.OCPolarity = LL_TIM_OCPOLARITY_HIGH;
  LL_TIM_OC_Init(TIM2, LL_TIM_CHANNEL_CH1, &TIM_OC_InitStruct);
  LL_TIM_OC_DisableFast(TIM2, LL_TIM_CHANNEL_CH1);
  LL_TIM_SetTriggerOutput(TIM2, LL_TIM_TRGO_RESET);
  LL_TIM_DisableMasterSlaveMode(TIM2);
  LL_AHB2_GRP1_EnableClock(LL_AHB2_GRP1_PERIPH_GPIOA);
  /**TIM2 GPIO Configuration
  PA0   ------> TIM2_CH1
  */
  GPIO_InitStruct.Pin = LL_GPIO_PIN_0;
  GPIO_InitStruct.Mode = LL_GPIO_MODE_ALTERNATE;
  GPIO_InitStruct.Speed = LL_GPIO_SPEED_FREQ_LOW;
  GPIO_InitStruct.OutputType = LL_GPIO_OUTPUT_PUSHPULL;
  GPIO_InitStruct.Pull = LL_GPIO_PULL_NO;
  GPIO_InitStruct.Alternate = LL_GPIO_AF_1;
  LL_GPIO_Init(GPIOA, &GPIO_InitStruct);

}

static void MX_TIM3_Init(void)
{

  LL_TIM_InitTypeDef TIM_InitStruct = {0};

  /* Peripheral clock enable */
  LL_APB1_GRP1_EnableClock(LL_APB1_GRP1_PERIPH_TIM3);

  /* TIM3 interrupt Init */
  NVIC_SetPriority(TIM3_IRQn, NVIC_EncodePriority(NVIC_GetPriorityGrouping(),1, 0));
  NVIC_EnableIRQ(TIM3_IRQn);

  TIM_InitStruct.Prescaler = ML_TIM_PSC;
  TIM_InitStruct.CounterMode = LL_TIM_COUNTERMODE_UP;
  TIM_InitStruct.Autoreload = ML_TIM_ARR;
  TIM_InitStruct.ClockDivision = LL_TIM_CLOCKDIVISION_DIV1;
  LL_TIM_Init(TIM3, &TIM_InitStruct);
  LL_TIM_DisableARRPreload(TIM3);
  LL_TIM_SetClockSource(TIM3, LL_TIM_CLOCKSOURCE_INTERNAL);
  LL_TIM_SetTriggerOutput(TIM3, LL_TIM_TRGO_RESET);
  LL_TIM_DisableMasterSlaveMode(TIM3);

}

static void MX_TIM8_Init(void)
{

  LL_TIM_InitTypeDef TIM_InitStruct = {0};

  /* Peripheral clock enable */
  LL_APB2_GRP1_EnableClock(LL_APB2_GRP1_PERIPH_TIM8);

  TIM_InitStruct.Prescaler = 27;
  TIM_InitStruct.CounterMode = LL_TIM_COUNTERMODE_UP;
  TIM_InitStruct.Autoreload = 249;
  TIM_InitStruct.ClockDivision = LL_TIM_CLOCKDIVISION_DIV1;
  TIM_InitStruct.RepetitionCounter = 0;
  LL_TIM_Init(TIM8, &TIM_InitStruct);
  LL_TIM_DisableARRPreload(TIM8);
  LL_TIM_SetClockSource(TIM8, LL_TIM_CLOCKSOURCE_INTERNAL);
  LL_TIM_SetTriggerOutput(TIM8, LL_TIM_TRGO_RESET);
  LL_TIM_SetTriggerOutput2(TIM8, LL_TIM_TRGO2_RESET);
  LL_TIM_DisableMasterSlaveMode(TIM8);

}

static void MX_TIM16_Init(void)
{

  LL_TIM_InitTypeDef TIM_InitStruct = {0};

  /* Peripheral clock enable */
  LL_APB2_GRP1_EnableClock(LL_APB2_GRP1_PERIPH_TIM16);

  TIM_InitStruct.Prescaler = 0;
  TIM_InitStruct.CounterMode = LL_TIM_COUNTERMODE_UP;
  TIM_InitStruct.Autoreload = 65535;
  TIM_InitStruct.ClockDivision = LL_TIM_CLOCKDIVISION_DIV1;
  TIM_InitStruct.RepetitionCounter = 0;
  LL_TIM_Init(TIM16, &TIM_InitStruct);
  LL_TIM_DisableARRPreload(TIM16);

}

static void MX_USART1_UART_Init(void)
{

  LL_USART_InitTypeDef USART_InitStruct = {0};

  LL_GPIO_InitTypeDef GPIO_InitStruct = {0};

  LL_RCC_SetUSARTClockSource(LL_RCC_USART1_CLKSOURCE_PCLK2);

  /* Peripheral clock enable */
  LL_APB2_GRP1_EnableClock(LL_APB2_GRP1_PERIPH_USART1);

  LL_AHB2_GRP1_EnableClock(LL_AHB2_GRP1_PERIPH_GPIOA);
  /**USART1 GPIO Configuration
  PA9   ------> USART1_TX
  PA10   ------> USART1_RX
  */
  GPIO_InitStruct.Pin = UART_TX_Pin;
  GPIO_InitStruct.Mode = LL_GPIO_MODE_ALTERNATE;
  GPIO_InitStruct.Speed = LL_GPIO_SPEED_FREQ_HIGH;
  GPIO_InitStruct.OutputType = LL_GPIO_OUTPUT_PUSHPULL;
  GPIO_InitStruct.Pull = LL_GPIO_PULL_NO;
  GPIO_InitStruct.Alternate = LL_GPIO_AF_7;
  LL_GPIO_Init(UART_TX_GPIO_Port, &GPIO_InitStruct);

  GPIO_InitStruct.Pin = UART_RX_Pin;
  GPIO_InitStruct.Mode = LL_GPIO_MODE_ALTERNATE;
  GPIO_InitStruct.Speed = LL_GPIO_SPEED_FREQ_HIGH;
  GPIO_InitStruct.OutputType = LL_GPIO_OUTPUT_PUSHPULL;
  GPIO_InitStruct.Pull = LL_GPIO_PULL_NO;
  GPIO_InitStruct.Alternate = LL_GPIO_AF_7;
  LL_GPIO_Init(UART_RX_GPIO_Port, &GPIO_InitStruct);

  /* USART1 interrupt Init */
  NVIC_SetPriority(USART1_IRQn, NVIC_EncodePriority(NVIC_GetPriorityGrouping(),2, 0));
  NVIC_EnableIRQ(USART1_IRQn);

  USART_InitStruct.PrescalerValue = LL_USART_PRESCALER_DIV1;
  USART_InitStruct.BaudRate = 115200;
  USART_InitStruct.DataWidth = LL_USART_DATAWIDTH_8B;
  USART_InitStruct.StopBits = LL_USART_STOPBITS_1;
  USART_InitStruct.Parity = LL_USART_PARITY_NONE;
  USART_InitStruct.TransferDirection = LL_USART_DIRECTION_TX_RX;
  USART_InitStruct.HardwareFlowControl = LL_USART_HWCONTROL_NONE;
  USART_InitStruct.OverSampling = LL_USART_OVERSAMPLING_16;
  LL_USART_Init(USART1, &USART_InitStruct);
  LL_USART_SetTXFIFOThreshold(USART1, LL_USART_FIFOTHRESHOLD_1_8);
  LL_USART_SetRXFIFOThreshold(USART1, LL_USART_FIFOTHRESHOLD_1_8);
  LL_USART_EnableFIFO(USART1);
  LL_USART_ConfigAsyncMode(USART1);

  LL_USART_Enable(USART1);

  /* Polling USART1 initialisation */
  while((!(LL_USART_IsActiveFlag_TEACK(USART1))) || (!(LL_USART_IsActiveFlag_REACK(USART1))))
  {
  }

}

static void MX_GPIO_Init(void)
{
  LL_GPIO_InitTypeDef GPIO_InitStruct = {0};

  /* GPIO Ports Clock Enable */
  LL_AHB2_GRP1_EnableClock(LL_AHB2_GRP1_PERIPH_GPIOF);
  LL_AHB2_GRP1_EnableClock(LL_AHB2_GRP1_PERIPH_GPIOA);
  LL_AHB2_GRP1_EnableClock(LL_AHB2_GRP1_PERIPH_GPIOC);
  LL_AHB2_GRP1_EnableClock(LL_AHB2_GRP1_PERIPH_GPIOB);
  LL_AHB2_GRP1_EnableClock(LL_AHB2_GRP1_PERIPH_GPIOE);

  /**/
  LL_GPIO_ResetOutputPin(GD_WAKE_GPIO_Port, GD_WAKE_Pin);

  /**/
  LL_GPIO_ResetOutputPin(GPIOA, LL_GPIO_PIN_15);

  /**/
  LL_GPIO_ResetOutputPin(ENC_SPI_nCS_GPIO_Port, ENC_SPI_nCS_Pin);

  /**/
  GPIO_InitStruct.Pin = GD_WAKE_Pin;
  GPIO_InitStruct.Mode = LL_GPIO_MODE_OUTPUT;
  GPIO_InitStruct.Speed = LL_GPIO_SPEED_FREQ_LOW;
  GPIO_InitStruct.OutputType = LL_GPIO_OUTPUT_PUSHPULL;
  GPIO_InitStruct.Pull = LL_GPIO_PULL_NO;
  LL_GPIO_Init(GD_WAKE_GPIO_Port, &GPIO_InitStruct);

  /**/
  GPIO_InitStruct.Pin = GD_READY_Pin;
  GPIO_InitStruct.Mode = LL_GPIO_MODE_INPUT;
  GPIO_InitStruct.Pull = LL_GPIO_PULL_UP;
  LL_GPIO_Init(GD_READY_GPIO_Port, &GPIO_InitStruct);

  /**/
  GPIO_InitStruct.Pin = LL_GPIO_PIN_15;
  GPIO_InitStruct.Mode = LL_GPIO_MODE_INPUT;
  GPIO_InitStruct.Pull = LL_GPIO_PULL_NO;
  LL_GPIO_Init(GPIOE, &GPIO_InitStruct);

  /**/
  GPIO_InitStruct.Pin = LL_GPIO_PIN_15;
  GPIO_InitStruct.Mode = LL_GPIO_MODE_OUTPUT;
  GPIO_InitStruct.Speed = LL_GPIO_SPEED_FREQ_LOW;
  GPIO_InitStruct.OutputType = LL_GPIO_OUTPUT_PUSHPULL;
  GPIO_InitStruct.Pull = LL_GPIO_PULL_NO;
  LL_GPIO_Init(GPIOA, &GPIO_InitStruct);

  /**/
  GPIO_InitStruct.Pin = LL_GPIO_PIN_3;
  GPIO_InitStruct.Mode = LL_GPIO_MODE_ALTERNATE;
  GPIO_InitStruct.Speed = LL_GPIO_SPEED_FREQ_LOW;
  GPIO_InitStruct.OutputType = LL_GPIO_OUTPUT_PUSHPULL;
  GPIO_InitStruct.Pull = LL_GPIO_PULL_NO;
  GPIO_InitStruct.Alternate = LL_GPIO_AF_6;
  LL_GPIO_Init(GPIOB, &GPIO_InitStruct);

  /**/
  GPIO_InitStruct.Pin = ENC_SPI_MISO_Pin;
  GPIO_InitStruct.Mode = LL_GPIO_MODE_ALTERNATE;
  GPIO_InitStruct.Speed = LL_GPIO_SPEED_FREQ_HIGH;
  GPIO_InitStruct.OutputType = LL_GPIO_OUTPUT_PUSHPULL;
  GPIO_InitStruct.Pull = LL_GPIO_PULL_NO;
  GPIO_InitStruct.Alternate = LL_GPIO_AF_5;
  LL_GPIO_Init(ENC_SPI_MISO_GPIO_Port, &GPIO_InitStruct);

  /**/
  GPIO_InitStruct.Pin = ENC_SPI_MOSI_Pin;
  GPIO_InitStruct.Mode = LL_GPIO_MODE_ALTERNATE;
  GPIO_InitStruct.Speed = LL_GPIO_SPEED_FREQ_HIGH;
  GPIO_InitStruct.OutputType = LL_GPIO_OUTPUT_PUSHPULL;
  GPIO_InitStruct.Pull = LL_GPIO_PULL_NO;
  GPIO_InitStruct.Alternate = LL_GPIO_AF_5;
  LL_GPIO_Init(ENC_SPI_MOSI_GPIO_Port, &GPIO_InitStruct);

  /**/
  GPIO_InitStruct.Pin = ENC_SPI_nCS_Pin;
  GPIO_InitStruct.Mode = LL_GPIO_MODE_OUTPUT;
  GPIO_InitStruct.Speed = LL_GPIO_SPEED_FREQ_LOW;
  GPIO_InitStruct.OutputType = LL_GPIO_OUTPUT_PUSHPULL;
  GPIO_InitStruct.Pull = LL_GPIO_PULL_NO;
  LL_GPIO_Init(ENC_SPI_nCS_GPIO_Port, &GPIO_InitStruct);

}

void Error_Handler(void)
{
  __disable_irq();
  while (1)
  {
  }
}
